# STM32WB06 register map
File version: 1.0
STM32WB06X
Registers are 32-bit, read-write, reset 0x0 unless marked. A register's access mark holds for its fields unless they carry their own. Offsets are from the block's base; lines under a group give offsets from that group; [hi:lo] are bit positions; {n}, {i} and the like mark numbered series; 'fields as' and 'values as' point back to an identical list; <NAME> marks a mode.

## Memory map
0x40000000 SYSCFG
0x40001000 FLASH
0x40002000 TIM1
0x40003000 IWDG
0x40004000 RTC
0x40005000 AHBUPCONV
0x41000000 I2C1
0x41001000 I2C2
0x41002000 SPI1
0x41003000 SPI2
0x41004000 USART1
0x41005000 LPUART1
0x41006000 ADC1
0x41007000 SPI3
0x48000000 GPIOA
0x48100000 GPIOB
0x48200000 CRC
0x48300000 PKA
0x48400000 RCC
0x48500000 PWR
0x48600000 RNG
0x48700000 DMA1
0x48800000 DMAMUX1
0x60000000 BLUE
0x60001000 RADIO_CTRL
0x60001400 RRM
0x60001800 WAKEUP

## Interrupts
0 FLASH — 0 NVM interrupt
1 RCC — 1 RCC interrupt
3 I2C1 — 3 I2C1 interrurpt
4 I2C2 — 4 I2C2 interrupt
5 SPI1 — 5 SPI1 interrupt
6 SPI2 — 6 SPI2 interrupt
7 SPI3 — 7 SPI3 interrupt
8 USART1 — 8 USART interrupt
9 LPUART1 — 9 Low Power UART interrupt
10 TIM1 — 10 Timer 1 interrupt
11 RTC — 11 RTC interrupt
12 ADC (ADC1) — 12 ADC interrupt
13 PKA — 13 PKA interrupt
15 GPIOA — 15 GPIOA interrupt
16 GPIOB — 16 GPIOB interrupt
17 DMA (DMA1) — 17 DMA interrupt
22 RADIO_RRM (RRM) — 22 RADIO Resource Manager interrupt

## SYSCFG
Base 0x40000000
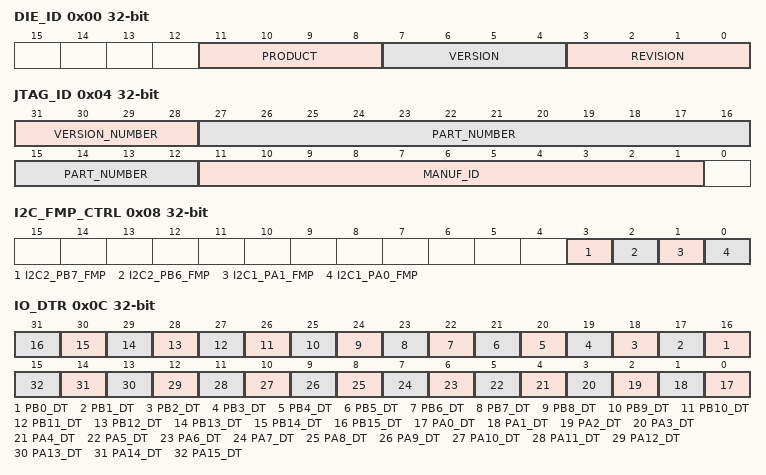
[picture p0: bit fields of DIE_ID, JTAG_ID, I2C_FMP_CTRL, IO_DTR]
0x00 DIE_ID
  [11:8] PRODUCT, [7:4] VERSION, [3:0] REVISION
0x04 JTAG_ID
  [31:28] VERSION_NUMBER, [27:12] PART_NUMBER, [11:1] MANUF_ID
0x08 I2C_FMP_CTRL
  [3] I2C2_PB7_FMP, [2] I2C2_PB6_FMP, [1] I2C1_PA1_FMP, [0] I2C1_PA0_FMP
0x0C IO_DTR
  [n+16] PB{n}_DT (n=0..15), [n] PA{n}_DT (n=0..15)
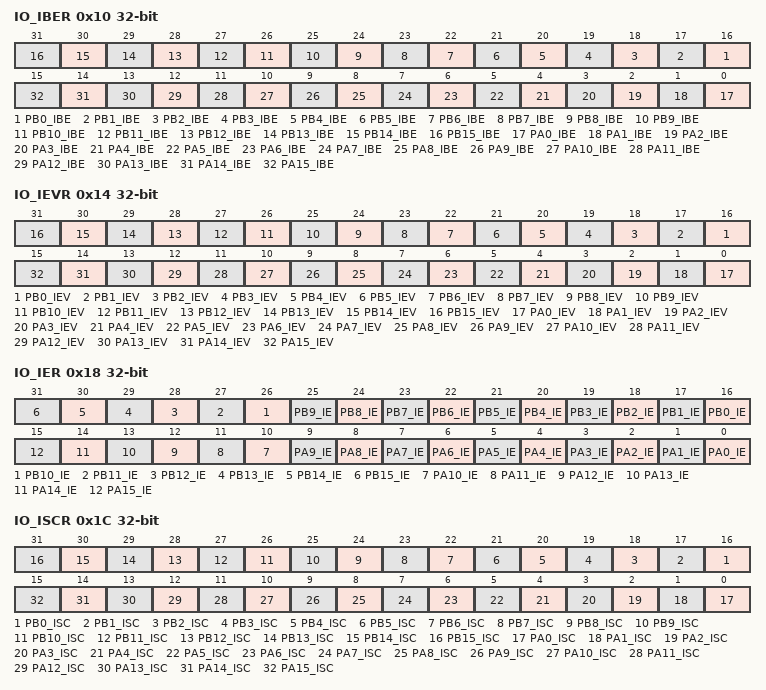
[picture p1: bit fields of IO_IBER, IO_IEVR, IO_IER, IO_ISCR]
0x10 IO_IBER
  [n+16] PB{n}_IBE (n=0..15), [n] PA{n}_IBE (n=0..15)
0x14 IO_IEVR
  [n+16] PB{n}_IEV (n=0..15), [n] PA{n}_IEV (n=0..15)
0x18 IO_IER
  [n+16] PB{n}_IE (n=0..15), [n] PA{n}_IE (n=0..15)
0x1C IO_ISCR
  [n+16] PB{n}_ISC (n=0..15), [n] PA{n}_ISC (n=0..15)
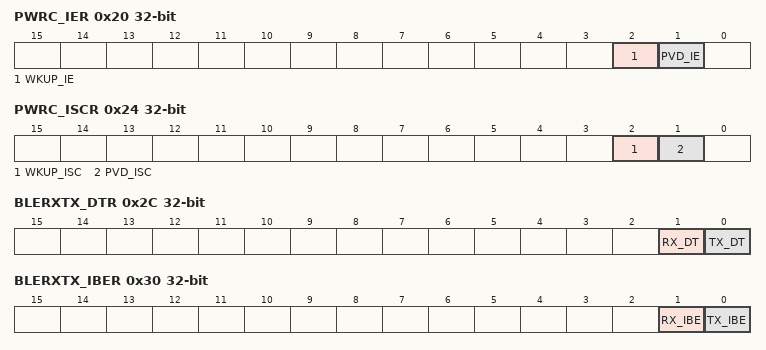
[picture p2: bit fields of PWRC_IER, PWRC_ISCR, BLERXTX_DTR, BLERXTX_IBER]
0x20 PWRC_IER
  [2] WKUP_IE, [1] PVD_IE
0x24 PWRC_ISCR
  [2] WKUP_ISC, [1] PVD_ISC
0x2C BLERXTX_DTR
  [1] RX_DT, [0] TX_DT
0x30 BLERXTX_IBER
  [1] RX_IBE, [0] TX_IBE
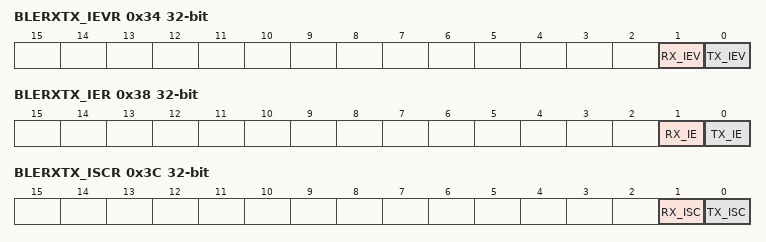
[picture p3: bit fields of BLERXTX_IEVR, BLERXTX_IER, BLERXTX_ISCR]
0x34 BLERXTX_IEVR
  [1] RX_IEV, [0] TX_IEV
0x38 BLERXTX_IER
  [1] RX_IE, [0] TX_IE
0x3C BLERXTX_ISCR
  [1] RX_ISC, [0] TX_ISC

## FLASH
Base 0x40001000
0x00 COMMAND
  [7:0] COMMAND
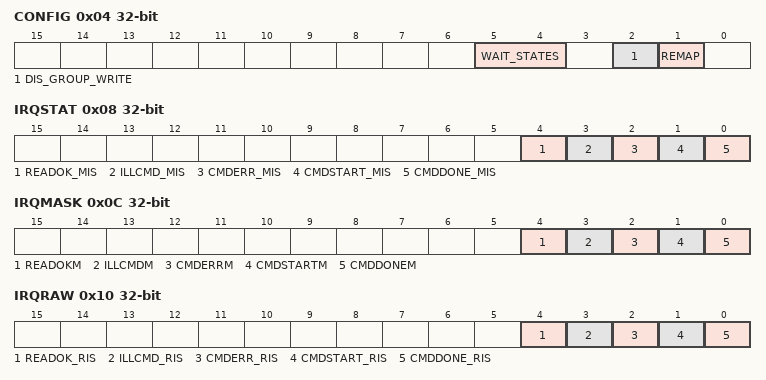
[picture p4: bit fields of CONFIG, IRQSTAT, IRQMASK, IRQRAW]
0x04 CONFIG
  [5:4] WAIT_STATES
  [2] DIS_GROUP_WRITE
  [1] REMAP
    0=FLASH (Main Flash memory mapped at 0x00000000); 1=SRAM (SRAM mapped at 0x00000000)
0x08 IRQSTAT
  [4] READOK_MIS, [3] ILLCMD_MIS, [2] CMDERR_MIS, [1] CMDSTART_MIS, [0] CMDDONE_MIS
0x0C IRQMASK
  [4] READOKM, [3] ILLCMDM, [2] CMDERRM, [1] CMDSTARTM, [0] CMDDONEM
0x10 IRQRAW
  [4] READOK_RIS, [3] ILLCMD_RIS, [2] CMDERR_RIS, [1] CMDSTART_RIS, [0] CMDDONE_RIS
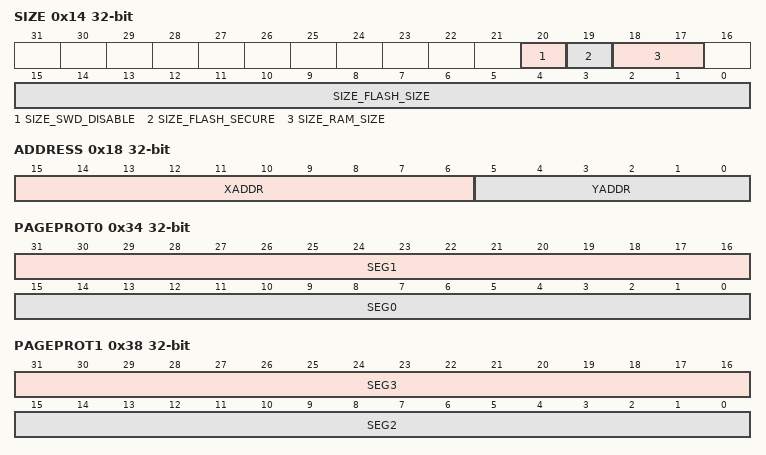
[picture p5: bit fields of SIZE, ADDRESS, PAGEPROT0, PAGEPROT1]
0x14 SIZE
  [20] SIZE_SWD_DISABLE, [19] SIZE_FLASH_SECURE, [18:17] SIZE_RAM_SIZE, [15:0] SIZE_FLASH_SIZE
0x18 ADDRESS
  [15:6] XADDR, [5:0] YADDR
0x24 LFSRVAL
0x34 PAGEPROT0
  [31:16] SEG1, [15:0] SEG0
0x38 PAGEPROT1
  [31:16] SEG3, [15:0] SEG2
{0x40+4i} DATA{i} (i=0..3)

## TIM1
Base 0x40002000
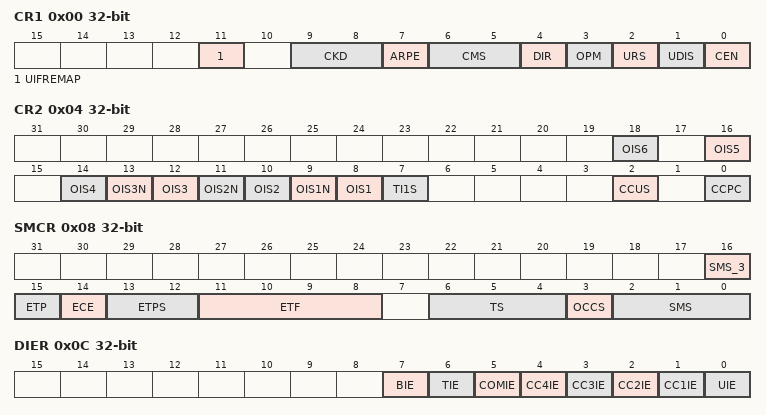
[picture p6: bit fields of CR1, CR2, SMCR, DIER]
0x00 CR1
  [11] UIFREMAP
  [9:8] CKD
    0=DIV1 (tDTS=tCK_INT); 1=DIV2 (tDTS=2*tCK_INT); 2=DIV4 (tDTS=4*tCK_INT)
  [7] ARPE
  [6:5] CMS
  [4] DIR
    0=UP (Timer counter counts up); 1=DOWN (Timer counter counts down)
  [3] OPM
    1=SINGLE (Counter stops counting at the next update event); 0=REPETITIVE (Counter is not stopped at update event)
  [2] URS
    0=REGULAR (Counter overflow/underflow, Setting the UG bit or Update generation through the slave mode controller generates an update request); 1=COUNTER (Only counter overflow/underflow generates an update request)
  [1] UDIS
  [0] CEN
0x04 CR2
  [2n+6] OIS{n} (n=1..6)
  [13] OIS3N
  [11] OIS2N
  [9] OIS1N
  [7] TI1S
  [2] CCUS
    0=ONLY (Capture/compare control bits are updated by setting the COMG bit only); 1=AND_TRGI (Capture/compare control bits are updated by setting the COMG bit or when a rising edge occurs on trigger input (TRGI))
  [0] CCPC
0x08 SMCR
  [16] SMS_3
  [15] ETP
  [14] ECE
  [13:12] ETPS
  [11:8] ETF
  [6:4] TS
    4=TI1F_ED (TI1 Edge Detector (TI1F_ED) is used as trigger input); 5=TI1FP1 (Filtered Timer Input 1 (TI1FP1) is used as trigger input); 6=TI2FP2 (Filtered Timer Input 2 (TI12P2) is used as trigger input); 7=ETRF (Filtered external Trigger (ETRF) is used as trigger input)
  [3] OCCS
    0=OCREF_CLR (OCREF_CLR_INT is connected to the OCREF_CLR input); 1=ETR (OCREF_CLR_INT is connected to ETRF)
  [2:0] SMS
0x0C DIER
  [7] BIE, [6] TIE, [5] COMIE, [n] CC{n}IE (n=1..4), [0] UIE
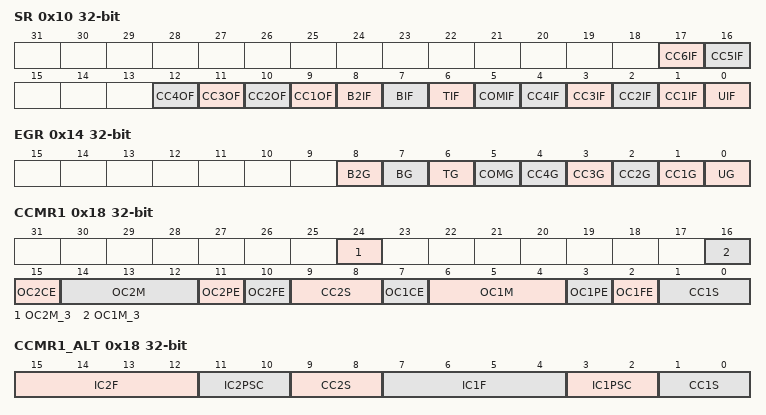
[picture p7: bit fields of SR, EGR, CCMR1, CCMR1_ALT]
0x10 SR
  [17] CC6IF, [16] CC5IF, [n+8] CC{n}OF (n=1..4), [8] B2IF, [7] BIF, [6] TIF, [5] COMIF, [n] CC{n}IF (n=1..4), [0] UIF
0x14 EGR
  [8] B2G, [7] BG, [6] TG, [5] COMG, [n] CC{n}G (n=1..4), [0] UG
0x18 CCMR1
  [24] OC2M_3, [16] OC1M_3, [15] OC2CE, [14:12] OC2M, [11] OC2PE, [10] OC2FE, [9:8] CC2S, [7] OC1CE, [6:4] OC1M, [3] OC1PE, [2] OC1FE, [1:0] CC1S
0x18 CCMR1_ALT (alternate view of CCMR1)
  [15:12] IC2F, [11:10] IC2PSC, [9:8] CC2S, [7:4] IC1F, [3:2] IC1PSC, [1:0] CC1S
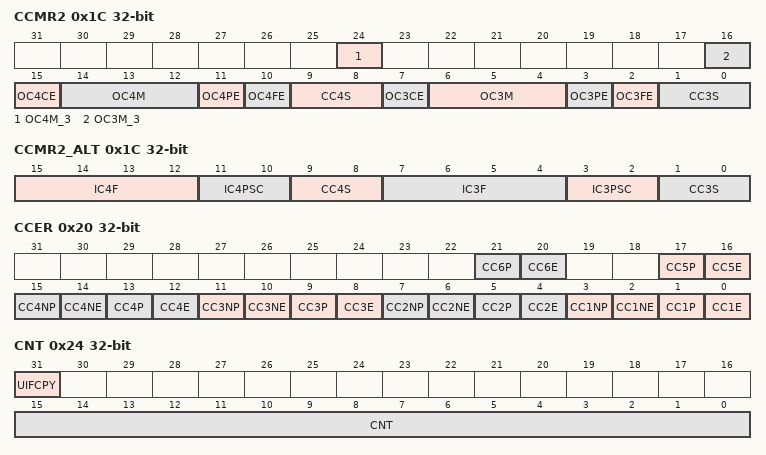
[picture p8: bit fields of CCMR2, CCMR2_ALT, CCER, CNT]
0x1C CCMR2
  [24] OC4M_3, [16] OC3M_3, [15] OC4CE, [14:12] OC4M, [11] OC4PE, [10] OC4FE, [9:8] CC4S, [7] OC3CE, [6:4] OC3M, [3] OC3PE, [2] OC3FE, [1:0] CC3S
0x1C CCMR2_ALT (alternate view of CCMR2)
  [15:12] IC4F, [11:10] IC4PSC, [9:8] CC4S, [7:4] IC3F, [3:2] IC3PSC, [1:0] CC3S
0x20 CCER
  [4n-3] CC{n}P (n=1..6), [4n-4] CC{n}E (n=1..6), [4n-1] CC{n}NP (n=1..4), [4n-2] CC{n}NE (n=1..4)
0x24 CNT
  [31] UIFCPY, [15:0] CNT
0x28 PSC
  [15:0] PSC
0x2C ARR
  [15:0] ARR
0x30 RCR
  [15:0] REP
{0x30+4i} CCR{i} (i=1..4)
  [15:0] CCR{i}
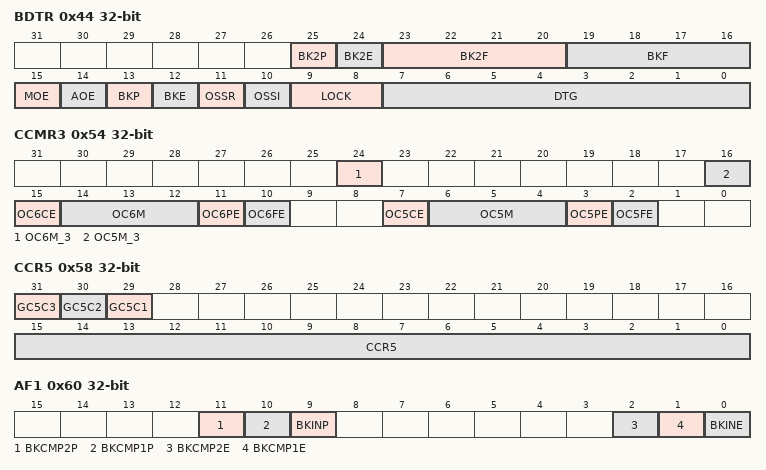
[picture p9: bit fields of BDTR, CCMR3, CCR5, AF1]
0x44 BDTR
  [25] BK2P
  [24] BK2E
  [23:20] BK2F
  [19:16] BKF
  [15] MOE
  [14] AOE
  [13] BKP
  [12] BKE
  [11] OSSR
  [10] OSSI
  [9:8] LOCK
    0=OFF (LOCK OFF - No bit is write protected); 1=LOCKLEVEL_1; 2=LOCKLEVEL_2; 3=LOCKLEVEL_3
  [7:0] DTG
0x54 CCMR3
  [24] OC6M_3, [16] OC5M_3, [15] OC6CE, [14:12] OC6M, [11] OC6PE, [10] OC6FE, [7] OC5CE, [6:4] OC5M, [3] OC5PE, [2] OC5FE
0x58 CCR5
  [31] GC5C3, [30] GC5C2, [29] GC5C1, [15:0] CCR5
0x5C CCR6
  [15:0] CCR6
0x60 AF1
  [11] BKCMP2P, [10] BKCMP1P, [9] BKINP, [2] BKCMP2E, [1] BKCMP1E, [0] BKINE
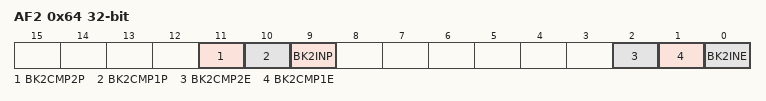
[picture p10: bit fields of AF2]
0x64 AF2
  [11] BK2CMP2P, [10] BK2CMP1P, [9] BK2INP, [2] BK2CMP2E, [1] BK2CMP1E, [0] BK2INE
